AUTOSAR XML (schema 314)
package /ComponentType
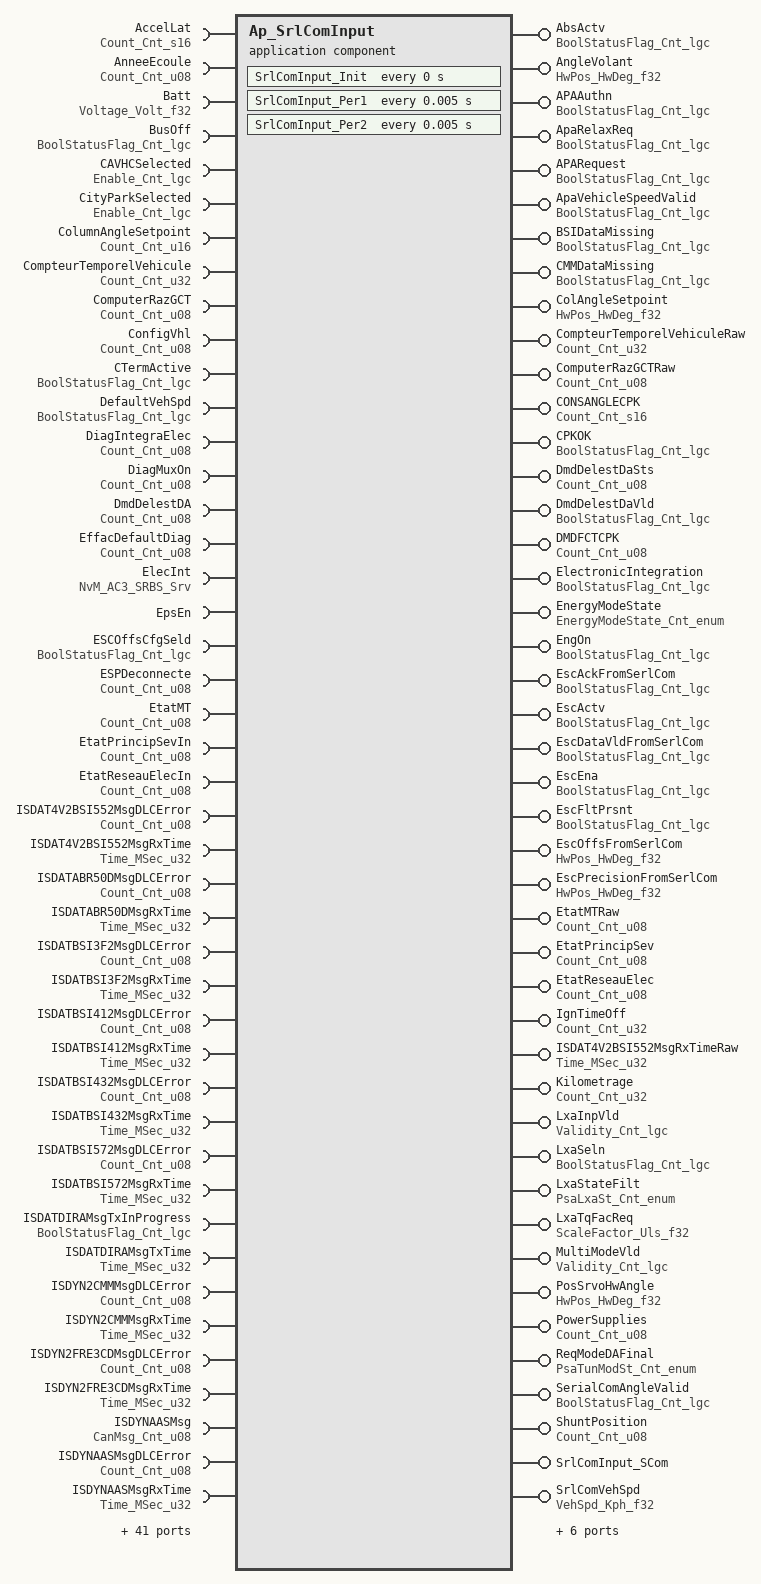
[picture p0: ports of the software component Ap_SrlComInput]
  application software component type Ap_SrlComInput
    50 x provide port:
      AbsActv: unqueued-sender-com-spec{data-element=Cnt_lgc, can-invalidate=false, init-value=D_FALSE_CNT_LGC}, provided-interface=BoolStatusFlag_Cnt_lgc
      AngleVolant: unqueued-sender-com-spec{data-element=HwDeg_f32, can-invalidate=false, init-value=D_ZERO_ULS_F32}, provided-interface=HwPos_HwDeg_f32
      APAAuthn: unqueued-sender-com-spec{data-element=Cnt_lgc, can-invalidate=false, init-value=D_FALSE_CNT_LGC}, provided-interface=BoolStatusFlag_Cnt_lgc
      ApaRelaxReq: unqueued-sender-com-spec{data-element=Cnt_lgc, can-invalidate=false, init-value=D_FALSE_CNT_LGC}, provided-interface=BoolStatusFlag_Cnt_lgc
      APARequest: unqueued-sender-com-spec{data-element=Cnt_lgc, can-invalidate=false, init-value=D_FALSE_CNT_LGC}, provided-interface=BoolStatusFlag_Cnt_lgc
      ApaVehicleSpeedValid: unqueued-sender-com-spec{data-element=Cnt_lgc, can-invalidate=false, init-value=D_FALSE_CNT_LGC}, provided-interface=BoolStatusFlag_Cnt_lgc
      BSIDataMissing: unqueued-sender-com-spec{data-element=Cnt_lgc, can-invalidate=false, init-value=D_TRUE_CNT_LGC}, provided-interface=BoolStatusFlag_Cnt_lgc
      CMMDataMissing: unqueued-sender-com-spec{data-element=Cnt_lgc, can-invalidate=false, init-value=D_TRUE_CNT_LGC}, provided-interface=BoolStatusFlag_Cnt_lgc
      ColAngleSetpoint: unqueued-sender-com-spec{data-element=HwDeg_f32, can-invalidate=false, init-value=D_ZERO_ULS_F32}, provided-interface=HwPos_HwDeg_f32
      CompteurTemporelVehiculeRaw: unqueued-sender-com-spec{data-element=Cnt_u32, can-invalidate=false, init-value=D_ZERO_CNT_U32}, provided-interface=Count_Cnt_u32
      ComputerRazGCTRaw: unqueued-sender-com-spec{data-element=Cnt_u08, can-invalidate=false, init-value=D_ZERO_CNT_U8}, provided-interface=Count_Cnt_u08
      CONSANGLECPK: unqueued-sender-com-spec{data-element=Cnt_s16, can-invalidate=false, init-value=D_ZERO_CNT_S16}, provided-interface=Count_Cnt_s16
      CPKOK: unqueued-sender-com-spec{data-element=Cnt_lgc, can-invalidate=false, init-value=D_FALSE_CNT_LGC}, provided-interface=BoolStatusFlag_Cnt_lgc
      DmdDelestDaSts: unqueued-sender-com-spec{data-element=Cnt_u08, can-invalidate=false, init-value=D_ZERO_CNT_U8}, provided-interface=Count_Cnt_u08
      DmdDelestDaVld: unqueued-sender-com-spec{data-element=Cnt_lgc, can-invalidate=false, init-value=D_FALSE_CNT_LGC}, provided-interface=BoolStatusFlag_Cnt_lgc
      DMDFCTCPK: unqueued-sender-com-spec{data-element=Cnt_u08, can-invalidate=false, init-value=D_ZERO_CNT_U8}, provided-interface=Count_Cnt_u08
      ElectronicIntegration: unqueued-sender-com-spec{data-element=Cnt_lgc, can-invalidate=false, init-value=D_FALSE_CNT_LGC}, provided-interface=BoolStatusFlag_Cnt_lgc
      EnergyModeState: unqueued-sender-com-spec{data-element=Cnt_enum, can-invalidate=false, init-value=D_NORMALINIT_CNT_U16}, provided-interface=EnergyModeState_Cnt_enum
      EngOn: unqueued-sender-com-spec{data-element=Cnt_lgc, can-invalidate=false, init-value=D_FALSE_CNT_LGC}, provided-interface=BoolStatusFlag_Cnt_lgc
      EscAckFromSerlCom: unqueued-sender-com-spec{data-element=Cnt_lgc, can-invalidate=false, init-value=D_FALSE_CNT_LGC}, provided-interface=BoolStatusFlag_Cnt_lgc
      EscActv: unqueued-sender-com-spec{data-element=Cnt_lgc, can-invalidate=false, init-value=D_FALSE_CNT_LGC}, provided-interface=BoolStatusFlag_Cnt_lgc
      EscDataVldFromSerlCom: unqueued-sender-com-spec{data-element=Cnt_lgc, can-invalidate=false, init-value=D_FALSE_CNT_LGC}, provided-interface=BoolStatusFlag_Cnt_lgc
      EscEna: unqueued-sender-com-spec{data-element=Cnt_lgc, can-invalidate=false, init-value=D_FALSE_CNT_LGC}, provided-interface=BoolStatusFlag_Cnt_lgc
      EscFltPrsnt: unqueued-sender-com-spec{data-element=Cnt_lgc, can-invalidate=false, init-value=D_TRUE_CNT_LGC}, provided-interface=BoolStatusFlag_Cnt_lgc
      EscOffsFromSerlCom: unqueued-sender-com-spec{data-element=HwDeg_f32, can-invalidate=false, init-value=D_ZERO_ULS_F32}, provided-interface=HwPos_HwDeg_f32
      EscPrecisionFromSerlCom: unqueued-sender-com-spec{data-element=HwDeg_f32, can-invalidate=false, init-value=D_ZERO_ULS_F32}, provided-interface=HwPos_HwDeg_f32
      EtatMTRaw: unqueued-sender-com-spec{data-element=Cnt_u08, can-invalidate=false, init-value=D_ZERO_CNT_U8}, provided-interface=Count_Cnt_u08
      EtatPrincipSev: unqueued-sender-com-spec{data-element=Cnt_u08, can-invalidate=false, init-value=D_ZERO_CNT_U8}, provided-interface=Count_Cnt_u08
      EtatReseauElec: unqueued-sender-com-spec{data-element=Cnt_u08, can-invalidate=false, init-value=D_ZERO_CNT_U8}, provided-interface=Count_Cnt_u08
      IgnTimeOff: unqueued-sender-com-spec{data-element=Cnt_u32, can-invalidate=false, init-value=D_ZERO_CNT_U32}, provided-interface=Count_Cnt_u32
      ISDAT4V2BSI552MsgRxTimeRaw: unqueued-sender-com-spec{data-element=MSec_u32, can-invalidate=false, init-value=D_ZERO_CNT_U32}, provided-interface=Time_MSec_u32
      Kilometrage: unqueued-sender-com-spec{data-element=Cnt_u32, can-invalidate=false, init-value=D_ZERO_CNT_U32}, provided-interface=Count_Cnt_u32
      LxaInpVld: unqueued-sender-com-spec{data-element=Cnt_lgc, can-invalidate=false, init-value=D_FALSE_CNT_LGC}, provided-interface=Validity_Cnt_lgc
      LxaSeln: unqueued-sender-com-spec{data-element=Cnt_lgc, can-invalidate=false, init-value=D_FALSE_CNT_LGC}, provided-interface=BoolStatusFlag_Cnt_lgc
      LxaStateFilt: unqueued-sender-com-spec{data-element=Cnt_enum, can-invalidate=false, init-value=D_PSALXASTINIT_CNT_ENUM}, provided-interface=PsaLxaSt_Cnt_enum
      LxaTqFacReq: unqueued-sender-com-spec{data-element=Uls_f32, can-invalidate=false, init-value=D_ZERO_ULS_F32}, provided-interface=ScaleFactor_Uls_f32
      MultiModeVld: unqueued-sender-com-spec{data-element=Cnt_lgc, can-invalidate=false, init-value=D_FALSE_CNT_LGC}, provided-interface=Validity_Cnt_lgc
      PosSrvoHwAngle: unqueued-sender-com-spec{data-element=HwDeg_f32, can-invalidate=false, init-value=D_ZERO_ULS_F32}, provided-interface=HwPos_HwDeg_f32
      PowerSupplies: unqueued-sender-com-spec{data-element=Cnt_u08, can-invalidate=false, init-value=D_ZERO_CNT_U8}, provided-interface=Count_Cnt_u08
      ReqModeDAFinal: unqueued-sender-com-spec{data-element=Cnt_enum, can-invalidate=false, init-value=D_PSATUNMODSTINIT_CNT_ENUM}, provided-interface=PsaTunModSt_Cnt_enum
      SerialComAngleValid: unqueued-sender-com-spec{data-element=Cnt_lgc, can-invalidate=false, init-value=D_FALSE_CNT_LGC}, provided-interface=BoolStatusFlag_Cnt_lgc
      ShuntPosition: unqueued-sender-com-spec{data-element=Cnt_u08, can-invalidate=false, init-value=D_ZERO_CNT_U8}, provided-interface=Count_Cnt_u08
      SrlComInput_SCom: provided-interface=SrlComInput_SCom
        provided-com-specs:
          operation=GetNetworkDiagFltAcc, queue-length=1
          operation=ManualVehSpd, queue-length=1
          operation=ResetTimers, queue-length=1
          operation=VehSpdControl, queue-length=1
      SrlComVehSpd: unqueued-sender-com-spec{data-element=Kph_f32, can-invalidate=false, init-value=D_ZERO_ULS_F32}, provided-interface=VehSpd_Kph_f32
      ValidEngineStatus: unqueued-sender-com-spec{data-element=Cnt_lgc, can-invalidate=false, init-value=D_FALSE_CNT_LGC}, provided-interface=BoolStatusFlag_Cnt_lgc
      VehicleLatAccel: unqueued-sender-com-spec{data-element=MpSecSq_f32, can-invalidate=false, init-value=D_ZERO_ULS_F32}, provided-interface=VehAccel_MpSecSq_f32
      VehicleLatAccelValid: unqueued-sender-com-spec{data-element=Cnt_lgc, can-invalidate=false, init-value=D_FALSE_CNT_LGC}, provided-interface=Validity_Cnt_lgc
      VehicleSpeedValid: unqueued-sender-com-spec{data-element=Cnt_lgc, can-invalidate=false, init-value=D_FALSE_CNT_LGC}, provided-interface=BoolStatusFlag_Cnt_lgc
      VehTimeValid: unqueued-sender-com-spec{data-element=Cnt_lgc, can-invalidate=false, init-value=D_FALSE_CNT_LGC}, provided-interface=BoolStatusFlag_Cnt_lgc
      VVHType: unqueued-sender-com-spec{data-element=Cnt_u08, can-invalidate=false, init-value=D_ZERO_CNT_U8}, provided-interface=Count_Cnt_u08
    85 x require port:
      AccelLat: unqueued-receiver-com-spec{data-element=Cnt_s16, init-value=D_ZERO_CNT_S16}, required-interface=Count_Cnt_s16
      AnneeEcoule: unqueued-receiver-com-spec{data-element=Cnt_u08, init-value=D_ZERO_CNT_U8}, required-interface=Count_Cnt_u08
      Batt: unqueued-receiver-com-spec{data-element=Volt_f32, init-value=D_ZERO_ULS_F32}, required-interface=Voltage_Volt_f32
      BusOff: unqueued-receiver-com-spec{data-element=Cnt_lgc, init-value=D_FALSE_CNT_LGC}, required-interface=BoolStatusFlag_Cnt_lgc
      CAVHCSelected: unqueued-receiver-com-spec{data-element=Cnt_lgc, init-value=D_FALSE_CNT_LGC}, required-interface=Enable_Cnt_lgc
      CityParkSelected: unqueued-receiver-com-spec{data-element=Cnt_lgc, init-value=D_FALSE_CNT_LGC}, required-interface=Enable_Cnt_lgc
      ColumnAngleSetpoint: unqueued-receiver-com-spec{data-element=Cnt_u16, init-value=D_ZERO_CNT_U16}, required-interface=Count_Cnt_u16
      CompteurTemporelVehicule: unqueued-receiver-com-spec{data-element=Cnt_u32, init-value=D_ZERO_CNT_U32}, required-interface=Count_Cnt_u32
      ComputerRazGCT: unqueued-receiver-com-spec{data-element=Cnt_u08, init-value=D_ZERO_CNT_U8}, required-interface=Count_Cnt_u08
      ConfigVhl: unqueued-receiver-com-spec{data-element=Cnt_u08, init-value=D_ZERO_CNT_U8}, required-interface=Count_Cnt_u08
      CTermActive: unqueued-receiver-com-spec{data-element=Cnt_lgc, init-value=D_FALSE_CNT_LGC}, required-interface=BoolStatusFlag_Cnt_lgc
      DefaultVehSpd: unqueued-receiver-com-spec{data-element=Cnt_lgc, init-value=D_FALSE_CNT_LGC}, required-interface=BoolStatusFlag_Cnt_lgc
      DiagIntegraElec: unqueued-receiver-com-spec{data-element=Cnt_u08, init-value=D_ZERO_CNT_U8}, required-interface=Count_Cnt_u08
      DiagMuxOn: unqueued-receiver-com-spec{data-element=Cnt_u08, init-value=D_ZERO_CNT_U8}, required-interface=Count_Cnt_u08
      DmdDelestDA: unqueued-receiver-com-spec{data-element=Cnt_u08, init-value=D_ZERO_CNT_U8}, required-interface=Count_Cnt_u08
      EffacDefaultDiag: unqueued-receiver-com-spec{data-element=Cnt_u08, init-value=D_ZERO_CNT_U8}, required-interface=Count_Cnt_u08
      ElecInt: required-com-specs=[EraseBlock, GetErrorStatus, InvalidateNvBlock, ReadBlock, SetRamBlockStatus, WriteBlock], required-interface=NvM_AC3_SRBS_Srv
      EpsEn: client-com-spec=OP_GET, required-interface=EpsEn
      ESCOffsCfgSeld: unqueued-receiver-com-spec{data-element=Cnt_lgc, init-value=D_FALSE_CNT_LGC}, required-interface=BoolStatusFlag_Cnt_lgc
      ESPDeconnecte: unqueued-receiver-com-spec{data-element=Cnt_u08, init-value=D_ONE_CNT_U8}, required-interface=Count_Cnt_u08
      EtatMT: unqueued-receiver-com-spec{data-element=Cnt_u08, init-value=D_ZERO_CNT_U8}, required-interface=Count_Cnt_u08
      EtatPrincipSevIn: unqueued-receiver-com-spec{data-element=Cnt_u08, init-value=D_ZERO_CNT_U8}, required-interface=Count_Cnt_u08
      EtatReseauElecIn: unqueued-receiver-com-spec{data-element=Cnt_u08, init-value=D_ZERO_CNT_U8}, required-interface=Count_Cnt_u08
      ISDAT4V2BSI552MsgDLCError: unqueued-receiver-com-spec{data-element=Cnt_u08, init-value=D_ZERO_CNT_U8}, required-interface=Count_Cnt_u08
      ISDAT4V2BSI552MsgRxTime: unqueued-receiver-com-spec{data-element=MSec_u32, init-value=D_ZERO_CNT_U32}, required-interface=Time_MSec_u32
      ISDATABR50DMsgDLCError: unqueued-receiver-com-spec{data-element=Cnt_u08, init-value=D_ZERO_CNT_U8}, required-interface=Count_Cnt_u08
      ISDATABR50DMsgRxTime: unqueued-receiver-com-spec{data-element=MSec_u32, init-value=D_ZERO_CNT_U32}, required-interface=Time_MSec_u32
      ISDATBSI3F2MsgDLCError: unqueued-receiver-com-spec{data-element=Cnt_u08, init-value=D_ZERO_CNT_U8}, required-interface=Count_Cnt_u08
      ISDATBSI3F2MsgRxTime: unqueued-receiver-com-spec{data-element=MSec_u32, init-value=D_ZERO_CNT_U32}, required-interface=Time_MSec_u32
      ISDATBSI412MsgDLCError: unqueued-receiver-com-spec{data-element=Cnt_u08, init-value=D_ZERO_CNT_U8}, required-interface=Count_Cnt_u08
      ISDATBSI412MsgRxTime: unqueued-receiver-com-spec{data-element=MSec_u32, init-value=D_ZERO_CNT_U32}, required-interface=Time_MSec_u32
      ISDATBSI432MsgDLCError: unqueued-receiver-com-spec{data-element=Cnt_u08, init-value=D_ZERO_CNT_U8}, required-interface=Count_Cnt_u08
      ISDATBSI432MsgRxTime: unqueued-receiver-com-spec{data-element=MSec_u32, init-value=D_ZERO_CNT_U32}, required-interface=Time_MSec_u32
      ISDATBSI572MsgDLCError: unqueued-receiver-com-spec{data-element=Cnt_u08, init-value=D_ZERO_CNT_U8}, required-interface=Count_Cnt_u08
      ISDATBSI572MsgRxTime: unqueued-receiver-com-spec{data-element=MSec_u32, init-value=D_ZERO_CNT_U32}, required-interface=Time_MSec_u32
      ISDATDIRAMsgTxInProgress: unqueued-receiver-com-spec{data-element=Cnt_lgc, init-value=D_FALSE_CNT_LGC}, required-interface=BoolStatusFlag_Cnt_lgc
      ISDATDIRAMsgTxTime: unqueued-receiver-com-spec{data-element=MSec_u32, init-value=D_ZERO_CNT_U32}, required-interface=Time_MSec_u32
      ISDYN2CMMMsgDLCError: unqueued-receiver-com-spec{data-element=Cnt_u08, init-value=D_ZERO_CNT_U8}, required-interface=Count_Cnt_u08
      ISDYN2CMMMsgRxTime: unqueued-receiver-com-spec{data-element=MSec_u32, init-value=D_ZERO_CNT_U32}, required-interface=Time_MSec_u32
      ISDYN2FRE3CDMsgDLCError: unqueued-receiver-com-spec{data-element=Cnt_u08, init-value=D_ZERO_CNT_U8}, required-interface=Count_Cnt_u08
      ISDYN2FRE3CDMsgRxTime: unqueued-receiver-com-spec{data-element=MSec_u32, init-value=D_ZERO_CNT_U32}, required-interface=Time_MSec_u32
      ISDYNAASMsg: unqueued-receiver-com-spec{data-element=Cnt_u08, init-value=T_CANMSGINIT_CNT_U08}, required-interface=CanMsg_Cnt_u08
      ISDYNAASMsgDLCError: unqueued-receiver-com-spec{data-element=Cnt_u08, init-value=D_ZERO_CNT_U8}, required-interface=Count_Cnt_u08
      ISDYNAASMsgRxTime: unqueued-receiver-com-spec{data-element=MSec_u32, init-value=D_ZERO_CNT_U32}, required-interface=Time_MSec_u32
      ISDYNABRMsg: unqueued-receiver-com-spec{data-element=Cnt_u08, init-value=T_CANMSGINIT_CNT_U08}, required-interface=CanMsg_Cnt_u08
      ISDYNABRMsgDLCError: unqueued-receiver-com-spec{data-element=Cnt_u08, init-value=D_ZERO_CNT_U8}, required-interface=Count_Cnt_u08
      ISDYNABRMsgRxTime: unqueued-receiver-com-spec{data-element=MSec_u32, init-value=D_ZERO_CNT_U32}, required-interface=Time_MSec_u32
      ISDYNCDS34DMsgDLCError: unqueued-receiver-com-spec{data-element=Cnt_u08, init-value=D_ZERO_CNT_U8}, required-interface=Count_Cnt_u08
      ISDYNCDS34DMsgRxTime: unqueued-receiver-com-spec{data-element=MSec_u32, init-value=D_ZERO_CNT_U32}, required-interface=Time_MSec_u32
      ISDYNCMM208MsgDLCError: unqueued-receiver-com-spec{data-element=Cnt_u08, init-value=D_ZERO_CNT_U8}, required-interface=Count_Cnt_u08
      ISDYNCMM208MsgRxTime: unqueued-receiver-com-spec{data-element=MSec_u32, init-value=D_ZERO_CNT_U32}, required-interface=Time_MSec_u32
      ISDYNCMM388MsgDLCError: unqueued-receiver-com-spec{data-element=Cnt_u08, init-value=D_ZERO_CNT_U8}, required-interface=Count_Cnt_u08
      ISDYNCMM388MsgRxTime: unqueued-receiver-com-spec{data-element=MSec_u32, init-value=D_ZERO_CNT_U32}, required-interface=Time_MSec_u32
      ISDYNVOLMsg: unqueued-receiver-com-spec{data-element=Cnt_u08, init-value=T_CANMSGINIT_CNT_U08}, required-interface=CanMsg_Cnt_u08
      ISDYNVOLMsgDLCError: unqueued-receiver-com-spec{data-element=Cnt_u08, init-value=D_ZERO_CNT_U8}, required-interface=Count_Cnt_u08
      ISDYNVOLMsgRxTime: unqueued-receiver-com-spec{data-element=MSec_u32, init-value=D_ZERO_CNT_U32}, required-interface=Time_MSec_u32
      ISINTEELECTRONBSIMsgRxTime: unqueued-receiver-com-spec{data-element=MSec_u32, init-value=D_ZERO_CNT_U32}, required-interface=Time_MSec_u32
      JourEcoule: unqueued-receiver-com-spec{data-element=Cnt_u16, init-value=D_ZERO_CNT_U16}, required-interface=Count_Cnt_u16
      KilometrageIn: unqueued-receiver-com-spec{data-element=Cnt_u32, init-value=D_ZERO_CNT_U32}, required-interface=Count_Cnt_u32
      LKAState: unqueued-receiver-com-spec{data-element=Cnt_u08, init-value=D_ZERO_CNT_U8}, required-interface=Count_Cnt_u08
      LKATrqFactReq: unqueued-receiver-com-spec{data-element=Cnt_u08, init-value=D_ZERO_CNT_U8}, required-interface=Count_Cnt_u08
      LXAActivation: unqueued-receiver-com-spec{data-element=Cnt_u08, init-value=D_ZERO_CNT_U8}, required-interface=Count_Cnt_u08
      LXASelected: unqueued-receiver-com-spec{data-element=Cnt_lgc, init-value=D_FALSE_CNT_LGC}, required-interface=Enable_Cnt_lgc
      ModeDiag: unqueued-receiver-com-spec{data-element=Cnt_u08, init-value=D_ZERO_CNT_U8}, required-interface=Count_Cnt_u08
      MultimodeSelected: unqueued-receiver-com-spec{data-element=Cnt_lgc, init-value=D_FALSE_CNT_LGC}, required-interface=Enable_Cnt_lgc
      NxtrDiagMgr: required-com-specs=[GetNTCActive, GetNTCFailed, GetNTCStatus, SetNTCStatus], required-interface=NxtrDiagMgr
      PowerSuppliesIn: unqueued-receiver-com-spec{data-element=Cnt_u08, init-value=D_ZERO_CNT_U8}, required-interface=Count_Cnt_u08
      PROTOHS1DYNUCF5CDMsg: unqueued-receiver-com-spec{data-element=Cnt_u08, init-value=T_CANMSGINIT_CNT_U08}, required-interface=CanMsg_Cnt_u08
      PROTOHS1DYNUCF5CDMsgDLCError: unqueued-receiver-com-spec{data-element=Cnt_u08, init-value=D_ZERO_CNT_U8}, required-interface=Count_Cnt_u08
      PROTOHS1DYNUCF5CDMsgRxTime: unqueued-receiver-com-spec{data-element=MSec_u32, init-value=D_ZERO_CNT_U32}, required-interface=Time_MSec_u32
      RegulAbr: unqueued-receiver-com-spec{data-element=Cnt_u08, init-value=D_ZERO_CNT_U8}, required-interface=Count_Cnt_u08
      RegulEsp: unqueued-receiver-com-spec{data-element=Cnt_u08, init-value=D_ZERO_CNT_U8}, required-interface=Count_Cnt_u08
      ReqLampeDefEsp: unqueued-receiver-com-spec{data-element=Cnt_u08, init-value=D_ZERO_CNT_U8}, required-interface=Count_Cnt_u08
      ReqModeDA: unqueued-receiver-com-spec{data-element=Cnt_u08, init-value=D_ZERO_CNT_U8}, required-interface=Count_Cnt_u08
      RxMsgsSrlComSvcDft: unqueued-receiver-com-spec{data-element=Cnt_lgc, init-value=D_FALSE_CNT_LGC}, required-interface=Enable_Cnt_lgc
      SecondeEcoulee: unqueued-receiver-com-spec{data-element=Cnt_u32, init-value=D_ZERO_CNT_U32}, required-interface=Count_Cnt_u32
      ShuntPositionIn: unqueued-receiver-com-spec{data-element=Cnt_u08, init-value=D_ZERO_CNT_U8}, required-interface=Count_Cnt_u08
      ShutdownTime: required-com-specs=[EraseBlock, GetErrorStatus, InvalidateNvBlock, ReadBlock, SetRamBlockStatus, WriteBlock], required-interface=NvM_AC3_SRBS_Srv
      SrlComDriver_SCom: required-com-specs=[ElecIntStart, ElecIntStop, GetBusOffCounter, SendMsgOnChange], required-interface=SrlComDriver_SCom
      STTdSelected: unqueued-receiver-com-spec{data-element=Cnt_lgc, init-value=D_FALSE_CNT_LGC}, required-interface=Enable_Cnt_lgc
      SystemState: required-interface=SystemState
      SystemTime: required-interface=SystemTime
        required-com-specs:
          DtrmnElapsedTime_mS_u16
          DtrmnElapsedTime_mS_u32
          DtrmnElapsedTime_uS_u16
          DtrmnElapsedTime_uS_u32
          GetSystemTime_mS_u32
          GetSystemTime_uS_u32
      VehicleSpeed: unqueued-receiver-com-spec{data-element=Kph_f32, init-value=D_ZERO_ULS_F32}, required-interface=VehSpd_Kph_f32
      VHHTYPE: required-com-specs=[EraseBlock, GetErrorStatus, InvalidateNvBlock, ReadBlock, SetRamBlockStatus, WriteBlock], required-interface=NvM_AC3_SRBS_Srv
      VitesseVehicleBV: unqueued-receiver-com-spec{data-element=Cnt_u16, init-value=D_ZERO_CNT_U16}, required-interface=Count_Cnt_u16
  internal behavior Ap_SrlComInput_InternalBehavior: component=Ap_SrlComInput
    timing event SrlComInput_InitEvent: start-on-event=SrlComInput_Init, period=0
    16 x data received event:
      DRT_SrlComInput_MsgIsDat4V2Bsi_552_ISDAT4V2BSI552MsgRxTime_MSec_u32: start-on-event=SrlComInput_MsgIsDat4V2Bsi_552, data=ISDAT4V2BSI552MsgRxTime.MSec_u32
      DRT_SrlComInput_MsgIsDatAbr_50D_ISDATABR50DMsgRxTime_MSec_u32: start-on-event=SrlComInput_MsgIsDatAbr_50D, data=ISDATABR50DMsgRxTime.MSec_u32
      DRT_SrlComInput_MsgIsDatBsi_3F2_ISDATBSI3F2MsgRxTime_MSec_u32: start-on-event=SrlComInput_MsgIsDatBsi_3F2, data=ISDATBSI3F2MsgRxTime.MSec_u32
      DRT_SrlComInput_MsgIsDatBsi_412_ISDATBSI412MsgRxTime_MSec_u32: start-on-event=SrlComInput_MsgIsDatBsi_412, data=ISDATBSI412MsgRxTime.MSec_u32
      DRT_SrlComInput_MsgIsDatBsi_432_ISDATBSI432MsgRxTime_MSec_u32: start-on-event=SrlComInput_MsgIsDatBsi_432, data=ISDATBSI432MsgRxTime.MSec_u32
      DRT_SrlComInput_MsgIsDatBsi_572_ISDATBSI572MsgRxTime_MSec_u32: start-on-event=SrlComInput_MsgIsDatBsi_572, data=ISDATBSI572MsgRxTime.MSec_u32
      DRT_SrlComInput_MsgIsDyn2Cmm_348_ISDYN2CMMMsgRxTime_MSec_u32: start-on-event=SrlComInput_MsgIsDyn2Cmm_348, data=ISDYN2CMMMsgRxTime.MSec_u32
      DRT_SrlComInput_MsgIsDyn2Fre_3CD_ISDYN2FRE3CDMsgRxTime_MSec_u32: start-on-event=SrlComInput_MsgIsDyn2Fre_3CD, data=ISDYN2FRE3CDMsgRxTime.MSec_u32
      DRT_SrlComInput_MsgIsDynAas_2EB_ISDYNAASMsgRxTime_MSec_u32: start-on-event=SrlComInput_MsgIsDynAas_2EB, data=ISDYNAASMsgRxTime.MSec_u32
      DRT_SrlComInput_MsgIsDynAbr_38D_ISDYNABRMsgRxTime_MSec_u32: start-on-event=SrlComInput_MsgIsDynAbr_38D, data=ISDYNABRMsgRxTime.MSec_u32
      DRT_SrlComInput_MsgIsDynCds_34D_ISDYNCDS34DMsgRxTime_MSec_u32: start-on-event=SrlComInput_MsgIsDynCds_34D, data=ISDYNCDS34DMsgRxTime.MSec_u32
      DRT_SrlComInput_MsgIsDynCmm_208_ISDYNCMM208MsgRxTime_MSec_u32: start-on-event=SrlComInput_MsgIsDynCmm_208, data=ISDYNCMM208MsgRxTime.MSec_u32
      DRT_SrlComInput_MsgIsDynCmm_388_ISDYNCMM388MsgRxTime_MSec_u32: start-on-event=SrlComInput_MsgIsDynCmm_388, data=ISDYNCMM388MsgRxTime.MSec_u32
      DRT_SrlComInput_MsgIsDynVol_305_ISDYNVOLMsgRxTime_MSec_u32: start-on-event=SrlComInput_MsgIsDynVol_305, data=ISDYNVOLMsgRxTime.MSec_u32
      DRT_SrlComInput_MsgIsInteElectronBsi_092_ISINTEELECTRONBSIMsgRxTime_MSec_u32: start-on-event=SrlComInput_MsgIsInteElectronBsi_092, data=ISINTEELECTRONBSIMsgRxTime.MSec_u32
      DRT_SrlComInput_MsgProtoHs1DynUcf_5CD_PROTOHS1DYNUCF5CDMsgRxTime_MSec_u32: start-on-event=SrlComInput_MsgProtoHs1DynUcf_5CD, data=PROTOHS1DYNUCF5CDMsgRxTime.MSec_u32
    timing event TMT_SrlComInput_Per1: start-on-event=SrlComInput_Per1, period=0.005
    timing event TMT_SrlComInput_Per2: start-on-event=SrlComInput_Per2, period=0.005
    4 x operation invoked event:
      OIT_SrlComInput_SCom_GetNetworkDiagFltAcc_SrlComInput_SCom_GetNetworkDiagFltAcc: start-on-event=SrlComInput_SCom_GetNetworkDiagFltAcc, operation=SrlComInput_SCom.GetNetworkDiagFltAcc
      OIT_SrlComInput_SCom_ManualVehSpd_SrlComInput_SCom_ManualVehSpd: start-on-event=SrlComInput_SCom_ManualVehSpd, operation=SrlComInput_SCom.ManualVehSpd
      OIT_SrlComInput_SCom_ResetTimers_SrlComInput_SCom_ResetTimers: start-on-event=SrlComInput_SCom_ResetTimers, operation=SrlComInput_SCom.ResetTimers
      OIT_SrlComInput_SCom_VehSpdControl_SrlComInput_SCom_VehSpdControl: start-on-event=SrlComInput_SCom_VehSpdControl, operation=SrlComInput_SCom.VehSpdControl
    mode switch event MST_SrlComInput_Trns1_0: start-on-event=SrlComInput_Trns1, activation=ENTRY, mode=SystemState.Mode.OFF
    mode switch event MST_SrlComInput_Trns2_0: start-on-event=SrlComInput_Trns2, activation=EXIT, mode=SystemState.Mode.OFF
    exclusive area DmdDelestDa
    exclusive area EaShutdownTimeData
    per instance memory ElecIntData: type=Boolean, type-definition=/DataType/Boolean
    per instance memory ShutdownTimeData: type=ShutdownTimeType, type-definition=/DataType/ShutdownTimeType
    per instance memory VVHTYPEData: type=UInt8, type-definition=/DataType/UInt8
    port-api-options:
      enable-take-address=false, indirect-api=false, port=AbsActv
      enable-take-address=false, indirect-api=false, port=AccelLat
      enable-take-address=false, indirect-api=false, port=AngleVolant
      enable-take-address=false, indirect-api=false, port=AnneeEcoule
      enable-take-address=false, indirect-api=false, port=APAAuthn
      enable-take-address=false, indirect-api=false, port=ApaRelaxReq
      enable-take-address=false, indirect-api=false, port=APARequest
      enable-take-address=false, indirect-api=false, port=ApaVehicleSpeedValid
      enable-take-address=false, indirect-api=false, port=Batt
      enable-take-address=false, indirect-api=false, port=BSIDataMissing
      enable-take-address=false, indirect-api=false, port=BusOff
      enable-take-address=false, indirect-api=false, port=CAVHCSelected
      enable-take-address=false, indirect-api=false, port=CityParkSelected
      enable-take-address=false, indirect-api=false, port=CMMDataMissing
      enable-take-address=false, indirect-api=false, port=ColAngleSetpoint
      enable-take-address=false, indirect-api=false, port=ColumnAngleSetpoint
      enable-take-address=false, indirect-api=false, port=CompteurTemporelVehicule
      enable-take-address=false, indirect-api=false, port=CompteurTemporelVehiculeRaw
      enable-take-address=false, indirect-api=false, port=ComputerRazGCT
      enable-take-address=false, indirect-api=false, port=ComputerRazGCTRaw
      enable-take-address=false, indirect-api=false, port=ConfigVhl
      enable-take-address=false, indirect-api=false, port=CONSANGLECPK
      enable-take-address=false, indirect-api=false, port=CPKOK
      enable-take-address=false, indirect-api=false, port=CTermActive
      enable-take-address=false, indirect-api=false, port=DefaultVehSpd
      enable-take-address=false, indirect-api=false, port=DiagIntegraElec
      enable-take-address=false, indirect-api=false, port=DiagMuxOn
      enable-take-address=false, indirect-api=false, port=DmdDelestDA
      enable-take-address=false, indirect-api=false, port=DmdDelestDaSts
      enable-take-address=false, indirect-api=false, port=DmdDelestDaVld
      enable-take-address=false, indirect-api=false, port=DMDFCTCPK
      enable-take-address=false, indirect-api=false, port=EffacDefaultDiag
      enable-take-address=false, indirect-api=false, port=ElecInt
      enable-take-address=false, indirect-api=false, port=ElectronicIntegration
      enable-take-address=false, indirect-api=false, port=EnergyModeState
      enable-take-address=false, indirect-api=false, port=EngOn
      enable-take-address=false, indirect-api=false, port=EpsEn
      enable-take-address=false, indirect-api=false, port=EscAckFromSerlCom
      enable-take-address=false, indirect-api=false, port=EscActv
      enable-take-address=false, indirect-api=false, port=EscDataVldFromSerlCom
      enable-take-address=false, indirect-api=false, port=EscEna
      enable-take-address=false, indirect-api=false, port=EscFltPrsnt
      enable-take-address=false, indirect-api=false, port=ESCOffsCfgSeld
      enable-take-address=false, indirect-api=false, port=EscOffsFromSerlCom
      enable-take-address=false, indirect-api=false, port=EscPrecisionFromSerlCom
      enable-take-address=false, indirect-api=false, port=ESPDeconnecte
      enable-take-address=false, indirect-api=false, port=EtatMT
      enable-take-address=false, indirect-api=false, port=EtatMTRaw
      enable-take-address=false, indirect-api=false, port=EtatPrincipSev
      enable-take-address=false, indirect-api=false, port=EtatPrincipSevIn
      enable-take-address=false, indirect-api=false, port=EtatReseauElec
      enable-take-address=false, indirect-api=false, port=EtatReseauElecIn
      enable-take-address=false, indirect-api=false, port=IgnTimeOff
      enable-take-address=false, indirect-api=false, port=ISDAT4V2BSI552MsgDLCError
      enable-take-address=false, indirect-api=false, port=ISDAT4V2BSI552MsgRxTime
      enable-take-address=false, indirect-api=false, port=ISDAT4V2BSI552MsgRxTimeRaw
      enable-take-address=false, indirect-api=false, port=ISDATABR50DMsgDLCError
      enable-take-address=false, indirect-api=false, port=ISDATABR50DMsgRxTime
      enable-take-address=false, indirect-api=false, port=ISDATBSI3F2MsgDLCError
      enable-take-address=false, indirect-api=false, port=ISDATBSI3F2MsgRxTime
      enable-take-address=false, indirect-api=false, port=ISDATBSI412MsgDLCError
      enable-take-address=false, indirect-api=false, port=ISDATBSI412MsgRxTime
      enable-take-address=false, indirect-api=false, port=ISDATBSI432MsgDLCError
      enable-take-address=false, indirect-api=false, port=ISDATBSI432MsgRxTime
      enable-take-address=false, indirect-api=false, port=ISDATBSI572MsgDLCError
      enable-take-address=false, indirect-api=false, port=ISDATBSI572MsgRxTime
      enable-take-address=false, indirect-api=false, port=ISDATDIRAMsgTxInProgress
      enable-take-address=false, indirect-api=false, port=ISDATDIRAMsgTxTime
      enable-take-address=false, indirect-api=false, port=ISDYN2CMMMsgDLCError
      enable-take-address=false, indirect-api=false, port=ISDYN2CMMMsgRxTime
      enable-take-address=false, indirect-api=false, port=ISDYN2FRE3CDMsgDLCError
      enable-take-address=false, indirect-api=false, port=ISDYN2FRE3CDMsgRxTime
      enable-take-address=false, indirect-api=false, port=ISDYNAASMsg
      enable-take-address=false, indirect-api=false, port=ISDYNAASMsgDLCError
      enable-take-address=false, indirect-api=false, port=ISDYNAASMsgRxTime
      enable-take-address=false, indirect-api=false, port=ISDYNABRMsg
      enable-take-address=false, indirect-api=false, port=ISDYNABRMsgDLCError
      enable-take-address=false, indirect-api=false, port=ISDYNABRMsgRxTime
      enable-take-address=false, indirect-api=false, port=ISDYNCDS34DMsgDLCError
      enable-take-address=false, indirect-api=false, port=ISDYNCDS34DMsgRxTime
      enable-take-address=false, indirect-api=false, port=ISDYNCMM208MsgDLCError
      enable-take-address=false, indirect-api=false, port=ISDYNCMM208MsgRxTime
      enable-take-address=false, indirect-api=false, port=ISDYNCMM388MsgDLCError
      enable-take-address=false, indirect-api=false, port=ISDYNCMM388MsgRxTime
      enable-take-address=false, indirect-api=false, port=ISDYNVOLMsg
      enable-take-address=false, indirect-api=false, port=ISDYNVOLMsgDLCError
      enable-take-address=false, indirect-api=false, port=ISDYNVOLMsgRxTime
      enable-take-address=false, indirect-api=false, port=ISINTEELECTRONBSIMsgRxTime
      enable-take-address=false, indirect-api=false, port=JourEcoule
      enable-take-address=false, indirect-api=false, port=Kilometrage
      enable-take-address=false, indirect-api=false, port=KilometrageIn
      enable-take-address=false, indirect-api=false, port=LKAState
      enable-take-address=false, indirect-api=false, port=LKATrqFactReq
      enable-take-address=false, indirect-api=false, port=LXAActivation
      enable-take-address=false, indirect-api=false, port=LxaInpVld
      enable-take-address=false, indirect-api=false, port=LXASelected
      enable-take-address=false, indirect-api=false, port=LxaSeln
      enable-take-address=false, indirect-api=false, port=LxaStateFilt
      enable-take-address=false, indirect-api=false, port=LxaTqFacReq
      enable-take-address=false, indirect-api=false, port=ModeDiag
      enable-take-address=false, indirect-api=false, port=MultimodeSelected
      enable-take-address=false, indirect-api=false, port=MultiModeVld
      enable-take-address=false, indirect-api=false, port=NxtrDiagMgr
      enable-take-address=false, indirect-api=false, port=PosSrvoHwAngle
      enable-take-address=false, indirect-api=false, port=PowerSupplies
      enable-take-address=false, indirect-api=false, port=PowerSuppliesIn
      enable-take-address=false, indirect-api=false, port=PROTOHS1DYNUCF5CDMsg
      enable-take-address=false, indirect-api=false, port=PROTOHS1DYNUCF5CDMsgDLCError
      enable-take-address=false, indirect-api=false, port=PROTOHS1DYNUCF5CDMsgRxTime
      enable-take-address=false, indirect-api=false, port=RegulAbr
      enable-take-address=false, indirect-api=false, port=RegulEsp
      enable-take-address=false, indirect-api=false, port=ReqLampeDefEsp
      enable-take-address=false, indirect-api=false, port=ReqModeDA
      enable-take-address=false, indirect-api=false, port=ReqModeDAFinal
      enable-take-address=false, indirect-api=false, port=RxMsgsSrlComSvcDft
      enable-take-address=false, indirect-api=false, port=SecondeEcoulee
      enable-take-address=false, indirect-api=false, port=SerialComAngleValid
      enable-take-address=false, indirect-api=false, port=ShuntPosition
      enable-take-address=false, indirect-api=false, port=ShuntPositionIn
      enable-take-address=false, indirect-api=false, port=ShutdownTime
      enable-take-address=false, indirect-api=false, port=SrlComDriver_SCom
      enable-take-address=false, indirect-api=false, port=SrlComInput_SCom
      enable-take-address=false, indirect-api=false, port=SrlComVehSpd
      enable-take-address=false, indirect-api=false, port=STTdSelected
      enable-take-address=false, indirect-api=false, port=SystemState
      enable-take-address=false, indirect-api=false, port=SystemTime
      enable-take-address=false, indirect-api=false, port=ValidEngineStatus
      enable-take-address=false, indirect-api=false, port=VehicleLatAccel
      enable-take-address=false, indirect-api=false, port=VehicleLatAccelValid
      enable-take-address=false, indirect-api=false, port=VehicleSpeed
      enable-take-address=false, indirect-api=false, port=VehicleSpeedValid
      enable-take-address=false, indirect-api=false, port=VehTimeValid
      enable-take-address=false, indirect-api=false, port=VHHTYPE
      enable-take-address=false, indirect-api=false, port=VitesseVehicleBV
      enable-take-address=false, indirect-api=false, port=VVHType
    25 x runnable:
      SrlComInput_Init
        6 x data read access:
          READ_CAVHCSelected_Cnt_lgc: data-element=CAVHCSelected.Cnt_lgc
          READ_CityParkSelected_Cnt_lgc: data-element=CityParkSelected.Cnt_lgc
          READ_ESCOffsCfgSeld_Cnt_lgc: data-element=ESCOffsCfgSeld.Cnt_lgc
          READ_LXASelected_Cnt_lgc: data-element=LXASelected.Cnt_lgc
          READ_MultimodeSelected_Cnt_lgc: data-element=MultimodeSelected.Cnt_lgc
          READ_STTdSelected_Cnt_lgc: data-element=STTdSelected.Cnt_lgc
        data send point SEND_VVHType_Cnt_u08: data-element=VVHType.Cnt_u08
        8 x data write access:
          WRITE_ApaVehicleSpeedValid_Cnt_lgc: data-element=ApaVehicleSpeedValid.Cnt_lgc
          WRITE_CPKOK_Cnt_lgc: data-element=CPKOK.Cnt_lgc
          WRITE_ElectronicIntegration_Cnt_lgc: data-element=ElectronicIntegration.Cnt_lgc
          WRITE_EnergyModeState_Cnt_enum: data-element=EnergyModeState.Cnt_enum
          WRITE_EscPrecisionFromSerlCom_HwDeg_f32: data-element=EscPrecisionFromSerlCom.HwDeg_f32
          WRITE_LxaInpVld_Cnt_lgc: data-element=LxaInpVld.Cnt_lgc
          WRITE_MultiModeVld_Cnt_lgc: data-element=MultiModeVld.Cnt_lgc
          WRITE_SrlComVehSpd_Kph_f32: data-element=SrlComVehSpd.Kph_f32
        sync call SC_NxtrDiagMgr_GetNTCFailed: operation=NxtrDiagMgr.GetNTCFailed, timeout=0
        sync call SC_NxtrDiagMgr_SetNTCStatus: operation=NxtrDiagMgr.SetNTCStatus, timeout=0
        sync call SC_SystemTime_GetSystemTime_mS_u32: operation=SystemTime.GetSystemTime_mS_u32, timeout=0
      SrlComInput_MsgIsDat4V2Bsi_552: can-enter-exclusive-area=EaShutdownTimeData
        7 x data receive point:
          REC_AnneeEcoule_Cnt_u08: data-element=AnneeEcoule.Cnt_u08
          REC_CompteurTemporelVehicule_Cnt_u32: data-element=CompteurTemporelVehicule.Cnt_u32
          REC_ISDAT4V2BSI552MsgDLCError_Cnt_u08: data-element=ISDAT4V2BSI552MsgDLCError.Cnt_u08
          REC_ISDAT4V2BSI552MsgRxTime_MSec_u32: data-element=ISDAT4V2BSI552MsgRxTime.MSec_u32
          REC_JourEcoule_Cnt_u16: data-element=JourEcoule.Cnt_u16
          REC_KilometrageIn_Cnt_u32: data-element=KilometrageIn.Cnt_u32
          REC_SecondeEcoulee_Cnt_u32: data-element=SecondeEcoulee.Cnt_u32
        data write access WRITE_CompteurTemporelVehiculeRaw_Cnt_u32: data-element=CompteurTemporelVehiculeRaw.Cnt_u32
        data write access WRITE_ISDAT4V2BSI552MsgRxTimeRaw_MSec_u32: data-element=ISDAT4V2BSI552MsgRxTimeRaw.MSec_u32
        data write access WRITE_Kilometrage_Cnt_u32: data-element=Kilometrage.Cnt_u32
        sync call SC_NxtrDiagMgr_GetNTCFailed: operation=NxtrDiagMgr.GetNTCFailed, timeout=0
        sync call SC_NxtrDiagMgr_SetNTCStatus: operation=NxtrDiagMgr.SetNTCStatus, timeout=0
      SrlComInput_MsgIsDatAbr_50D
        data receive point REC_ISDATABR50DMsgDLCError_Cnt_u08: data-element=ISDATABR50DMsgDLCError.Cnt_u08
        data receive point REC_ISDATABR50DMsgRxTime_MSec_u32: data-element=ISDATABR50DMsgRxTime.MSec_u32
        sync call SC_NxtrDiagMgr_SetNTCStatus: operation=NxtrDiagMgr.SetNTCStatus, timeout=0
      SrlComInput_MsgIsDatBsi_3F2
        6 x data receive point:
          REC_ColumnAngleSetpoint_Cnt_u16: data-element=ColumnAngleSetpoint.Cnt_u16
          REC_ISDATBSI3F2MsgDLCError_Cnt_u08: data-element=ISDATBSI3F2MsgDLCError.Cnt_u08
          REC_ISDATBSI3F2MsgRxTime_MSec_u32: data-element=ISDATBSI3F2MsgRxTime.MSec_u32
          REC_LKAState_Cnt_u08: data-element=LKAState.Cnt_u08
          REC_LKATrqFactReq_Cnt_u08: data-element=LKATrqFactReq.Cnt_u08
          REC_LXAActivation_Cnt_u08: data-element=LXAActivation.Cnt_u08
        data write access WRITE_LxaSeln_Cnt_lgc: data-element=LxaSeln.Cnt_lgc
        data write access WRITE_LxaTqFacReq_Uls_f32: data-element=LxaTqFacReq.Uls_f32
        sync call SC_NxtrDiagMgr_SetNTCStatus: operation=NxtrDiagMgr.SetNTCStatus, timeout=0
      SrlComInput_MsgIsDatBsi_412
        data receive point REC_ISDATBSI412MsgDLCError_Cnt_u08: data-element=ISDATBSI412MsgDLCError.Cnt_u08
        data receive point REC_ISDATBSI412MsgRxTime_MSec_u32: data-element=ISDATBSI412MsgRxTime.MSec_u32
        data receive point REC_ReqModeDA_Cnt_u08: data-element=ReqModeDA.Cnt_u08
        sync call SC_NxtrDiagMgr_SetNTCStatus: operation=NxtrDiagMgr.SetNTCStatus, timeout=0
      SrlComInput_MsgIsDatBsi_432
        6 x data receive point:
          REC_EtatPrincipSevIn_Cnt_u08: data-element=EtatPrincipSevIn.Cnt_u08
          REC_EtatReseauElecIn_Cnt_u08: data-element=EtatReseauElecIn.Cnt_u08
          REC_ISDATBSI432MsgDLCError_Cnt_u08: data-element=ISDATBSI432MsgDLCError.Cnt_u08
          REC_ISDATBSI432MsgRxTime_MSec_u32: data-element=ISDATBSI432MsgRxTime.MSec_u32
          REC_PowerSuppliesIn_Cnt_u08: data-element=PowerSuppliesIn.Cnt_u08
          REC_ShuntPositionIn_Cnt_u08: data-element=ShuntPositionIn.Cnt_u08
        4 x data write access:
          WRITE_EtatPrincipSev_Cnt_u08: data-element=EtatPrincipSev.Cnt_u08
          WRITE_EtatReseauElec_Cnt_u08: data-element=EtatReseauElec.Cnt_u08
          WRITE_PowerSupplies_Cnt_u08: data-element=PowerSupplies.Cnt_u08
          WRITE_ShuntPosition_Cnt_u08: data-element=ShuntPosition.Cnt_u08
        sync call SC_NxtrDiagMgr_SetNTCStatus: operation=NxtrDiagMgr.SetNTCStatus, timeout=0
      SrlComInput_MsgIsDatBsi_572
        data receive point REC_ConfigVhl_Cnt_u08: data-element=ConfigVhl.Cnt_u08
        data receive point REC_ISDATBSI572MsgDLCError_Cnt_u08: data-element=ISDATBSI572MsgDLCError.Cnt_u08
        data receive point REC_ISDATBSI572MsgRxTime_MSec_u32: data-element=ISDATBSI572MsgRxTime.MSec_u32
        sync call SC_NxtrDiagMgr_SetNTCStatus: operation=NxtrDiagMgr.SetNTCStatus, timeout=0
      SrlComInput_MsgIsDyn2Cmm_348
        data receive point REC_ISDYN2CMMMsgDLCError_Cnt_u08: data-element=ISDYN2CMMMsgDLCError.Cnt_u08
        data receive point REC_ISDYN2CMMMsgRxTime_MSec_u32: data-element=ISDYN2CMMMsgRxTime.MSec_u32
        sync call SC_NxtrDiagMgr_SetNTCStatus: operation=NxtrDiagMgr.SetNTCStatus, timeout=0
      SrlComInput_MsgIsDyn2Fre_3CD
        data receive point REC_AccelLat_Cnt_s16: data-element=AccelLat.Cnt_s16
        data receive point REC_ISDYN2FRE3CDMsgDLCError_Cnt_u08: data-element=ISDYN2FRE3CDMsgDLCError.Cnt_u08
        data receive point REC_ISDYN2FRE3CDMsgRxTime_MSec_u32: data-element=ISDYN2FRE3CDMsgRxTime.MSec_u32
        sync call SC_NxtrDiagMgr_SetNTCStatus: operation=NxtrDiagMgr.SetNTCStatus, timeout=0
      SrlComInput_MsgIsDynAas_2EB
        data receive point REC_ISDYNAASMsg_Cnt_u08: data-element=ISDYNAASMsg.Cnt_u08
        data receive point REC_ISDYNAASMsgDLCError_Cnt_u08: data-element=ISDYNAASMsgDLCError.Cnt_u08
        data receive point REC_ISDYNAASMsgRxTime_MSec_u32: data-element=ISDYNAASMsgRxTime.MSec_u32
        sync call SC_NxtrDiagMgr_SetNTCStatus: operation=NxtrDiagMgr.SetNTCStatus, timeout=0
      SrlComInput_MsgIsDynAbr_38D
        data receive point REC_ISDYNABRMsg_Cnt_u08: data-element=ISDYNABRMsg.Cnt_u08
        data receive point REC_ISDYNABRMsgDLCError_Cnt_u08: data-element=ISDYNABRMsgDLCError.Cnt_u08
        data receive point REC_ISDYNABRMsgRxTime_MSec_u32: data-element=ISDYNABRMsgRxTime.MSec_u32
        data send point SEND_VVHType_Cnt_u08: data-element=VVHType.Cnt_u08
        sync call SC_NxtrDiagMgr_SetNTCStatus: operation=NxtrDiagMgr.SetNTCStatus, timeout=0
        sync call SC_VHHTYPE_WriteBlock: operation=VHHTYPE.WriteBlock, timeout=0
      SrlComInput_MsgIsDynCds_34D
        data receive point REC_ISDYNCDS34DMsgDLCError_Cnt_u08: data-element=ISDYNCDS34DMsgDLCError.Cnt_u08
        data receive point REC_ISDYNCDS34DMsgRxTime_MSec_u32: data-element=ISDYNCDS34DMsgRxTime.MSec_u32
        sync call SC_NxtrDiagMgr_SetNTCStatus: operation=NxtrDiagMgr.SetNTCStatus, timeout=0
      SrlComInput_MsgIsDynCmm_208
        data receive point REC_ISDYNCMM208MsgDLCError_Cnt_u08: data-element=ISDYNCMM208MsgDLCError.Cnt_u08
        data receive point REC_ISDYNCMM208MsgRxTime_MSec_u32: data-element=ISDYNCMM208MsgRxTime.MSec_u32
        sync call SC_NxtrDiagMgr_SetNTCStatus: operation=NxtrDiagMgr.SetNTCStatus, timeout=0
      SrlComInput_MsgIsDynCmm_388
        data receive point REC_ISDYNCMM388MsgDLCError_Cnt_u08: data-element=ISDYNCMM388MsgDLCError.Cnt_u08
        data receive point REC_ISDYNCMM388MsgRxTime_MSec_u32: data-element=ISDYNCMM388MsgRxTime.MSec_u32
        data receive point REC_VitesseVehicleBV_Cnt_u16: data-element=VitesseVehicleBV.Cnt_u16
        data send point SEND_VVHType_Cnt_u08: data-element=VVHType.Cnt_u08
        sync call SC_NxtrDiagMgr_SetNTCStatus: operation=NxtrDiagMgr.SetNTCStatus, timeout=0
        sync call SC_VHHTYPE_WriteBlock: operation=VHHTYPE.WriteBlock, timeout=0
      SrlComInput_MsgIsDynVol_305
        data receive point REC_ISDYNVOLMsg_Cnt_u08: data-element=ISDYNVOLMsg.Cnt_u08
        data receive point REC_ISDYNVOLMsgDLCError_Cnt_u08: data-element=ISDYNVOLMsgDLCError.Cnt_u08
        data receive point REC_ISDYNVOLMsgRxTime_MSec_u32: data-element=ISDYNVOLMsgRxTime.MSec_u32
        sync call SC_NxtrDiagMgr_SetNTCStatus: operation=NxtrDiagMgr.SetNTCStatus, timeout=0
      SrlComInput_MsgIsInteElectronBsi_092
        data receive point REC_DiagIntegraElec_Cnt_u08: data-element=DiagIntegraElec.Cnt_u08
        data receive point REC_EffacDefaultDiag_Cnt_u08: data-element=EffacDefaultDiag.Cnt_u08
        data receive point REC_ModeDiag_Cnt_u08: data-element=ModeDiag.Cnt_u08
        sync call SC_SystemTime_DtrmnElapsedTime_mS_u16: operation=SystemTime.DtrmnElapsedTime_mS_u16, timeout=0
      SrlComInput_MsgProtoHs1DynUcf_5CD
        data receive point REC_PROTOHS1DYNUCF5CDMsg_Cnt_u08: data-element=PROTOHS1DYNUCF5CDMsg.Cnt_u08
        data receive point REC_PROTOHS1DYNUCF5CDMsgDLCError_Cnt_u08: data-element=PROTOHS1DYNUCF5CDMsgDLCError.Cnt_u08
        data receive point REC_PROTOHS1DYNUCF5CDMsgRxTime_MSec_u32: data-element=PROTOHS1DYNUCF5CDMsgRxTime.MSec_u32
        sync call SC_NxtrDiagMgr_SetNTCStatus: operation=NxtrDiagMgr.SetNTCStatus, timeout=0
        sync call SC_SystemTime_DtrmnElapsedTime_mS_u16: operation=SystemTime.DtrmnElapsedTime_mS_u16, timeout=0
        sync call SC_SystemTime_GetSystemTime_mS_u32: operation=SystemTime.GetSystemTime_mS_u32, timeout=0
      SrlComInput_Per1
        6 x data read access:
          READ_Batt_Volt_f32: data-element=Batt.Volt_f32
          READ_BusOff_Cnt_lgc: data-element=BusOff.Cnt_lgc
          READ_CTermActive_Cnt_lgc: data-element=CTermActive.Cnt_lgc
          READ_ESCOffsCfgSeld_Cnt_lgc: data-element=ESCOffsCfgSeld.Cnt_lgc
          READ_RxMsgsSrlComSvcDft_Cnt_lgc: data-element=RxMsgsSrlComSvcDft.Cnt_lgc
          READ_VehicleSpeed_Kph_f32: data-element=VehicleSpeed.Kph_f32
        25 x data receive point:
          REC_AnneeEcoule_Cnt_u08: data-element=AnneeEcoule.Cnt_u08
          REC_CompteurTemporelVehicule_Cnt_u32: data-element=CompteurTemporelVehicule.Cnt_u32
          REC_ComputerRazGCT_Cnt_u08: data-element=ComputerRazGCT.Cnt_u08
          REC_DiagMuxOn_Cnt_u08: data-element=DiagMuxOn.Cnt_u08
          REC_DmdDelestDA_Cnt_u08: data-element=DmdDelestDA.Cnt_u08
          REC_EtatMT_Cnt_u08: data-element=EtatMT.Cnt_u08
          REC_ISDAT4V2BSI552MsgRxTime_MSec_u32: data-element=ISDAT4V2BSI552MsgRxTime.MSec_u32
          REC_ISDATABR50DMsgRxTime_MSec_u32: data-element=ISDATABR50DMsgRxTime.MSec_u32
          REC_ISDATBSI3F2MsgRxTime_MSec_u32: data-element=ISDATBSI3F2MsgRxTime.MSec_u32
          REC_ISDATBSI412MsgRxTime_MSec_u32: data-element=ISDATBSI412MsgRxTime.MSec_u32
          REC_ISDATBSI432MsgRxTime_MSec_u32: data-element=ISDATBSI432MsgRxTime.MSec_u32
          REC_ISDATBSI572MsgRxTime_MSec_u32: data-element=ISDATBSI572MsgRxTime.MSec_u32
          REC_ISDATDIRAMsgTxInProgress_Cnt_lgc: data-element=ISDATDIRAMsgTxInProgress.Cnt_lgc
          REC_ISDATDIRAMsgTxTime_MSec_u32: data-element=ISDATDIRAMsgTxTime.MSec_u32
          REC_ISDYN2CMMMsgRxTime_MSec_u32: data-element=ISDYN2CMMMsgRxTime.MSec_u32
          REC_ISDYN2FRE3CDMsgRxTime_MSec_u32: data-element=ISDYN2FRE3CDMsgRxTime.MSec_u32
          REC_ISDYNAASMsgRxTime_MSec_u32: data-element=ISDYNAASMsgRxTime.MSec_u32
          REC_ISDYNABRMsgRxTime_MSec_u32: data-element=ISDYNABRMsgRxTime.MSec_u32
          REC_ISDYNCDS34DMsgRxTime_MSec_u32: data-element=ISDYNCDS34DMsgRxTime.MSec_u32
          REC_ISDYNCMM208MsgRxTime_MSec_u32: data-element=ISDYNCMM208MsgRxTime.MSec_u32
          REC_ISDYNCMM388MsgRxTime_MSec_u32: data-element=ISDYNCMM388MsgRxTime.MSec_u32
          REC_ISDYNVOLMsgRxTime_MSec_u32: data-element=ISDYNVOLMsgRxTime.MSec_u32
          REC_JourEcoule_Cnt_u16: data-element=JourEcoule.Cnt_u16
          REC_PROTOHS1DYNUCF5CDMsgRxTime_MSec_u32: data-element=PROTOHS1DYNUCF5CDMsgRxTime.MSec_u32
          REC_SecondeEcoulee_Cnt_u32: data-element=SecondeEcoulee.Cnt_u32
        data write access WRITE_ComputerRazGCTRaw_Cnt_u08: data-element=ComputerRazGCTRaw.Cnt_u08
        data write access WRITE_EtatMTRaw_Cnt_u08: data-element=EtatMTRaw.Cnt_u08
        5 x sync call, all with timeout=0:
          SC_EpsEn_OP_GET: operation=EpsEn.OP_GET
          SC_NxtrDiagMgr_GetNTCFailed: operation=NxtrDiagMgr.GetNTCFailed
          SC_NxtrDiagMgr_SetNTCStatus: operation=NxtrDiagMgr.SetNTCStatus
          SC_SystemTime_DtrmnElapsedTime_mS_u16: operation=SystemTime.DtrmnElapsedTime_mS_u16
          SC_SystemTime_GetSystemTime_mS_u32: operation=SystemTime.GetSystemTime_mS_u32
      SrlComInput_Per2: can-enter-exclusive-area=DmdDelestDa
        data read access READ_DefaultVehSpd_Cnt_lgc: data-element=DefaultVehSpd.Cnt_lgc
        4 x data receive point:
          REC_ESPDeconnecte_Cnt_u08: data-element=ESPDeconnecte.Cnt_u08
          REC_RegulAbr_Cnt_u08: data-element=RegulAbr.Cnt_u08
          REC_RegulEsp_Cnt_u08: data-element=RegulEsp.Cnt_u08
          REC_ReqLampeDefEsp_Cnt_u08: data-element=ReqLampeDefEsp.Cnt_u08
        data send point SEND_DmdDelestDaSts_Cnt_u08: data-element=DmdDelestDaSts.Cnt_u08
        data send point SEND_DmdDelestDaVld_Cnt_lgc: data-element=DmdDelestDaVld.Cnt_lgc
        35 x data write access:
          WRITE_AbsActv_Cnt_lgc: data-element=AbsActv.Cnt_lgc
          WRITE_AngleVolant_HwDeg_f32: data-element=AngleVolant.HwDeg_f32
          WRITE_APAAuthn_Cnt_lgc: data-element=APAAuthn.Cnt_lgc
          WRITE_ApaRelaxReq_Cnt_lgc: data-element=ApaRelaxReq.Cnt_lgc
          WRITE_APARequest_Cnt_lgc: data-element=APARequest.Cnt_lgc
          WRITE_ApaVehicleSpeedValid_Cnt_lgc: data-element=ApaVehicleSpeedValid.Cnt_lgc
          WRITE_BSIDataMissing_Cnt_lgc: data-element=BSIDataMissing.Cnt_lgc
          WRITE_CMMDataMissing_Cnt_lgc: data-element=CMMDataMissing.Cnt_lgc
          WRITE_ColAngleSetpoint_HwDeg_f32: data-element=ColAngleSetpoint.HwDeg_f32
          WRITE_CONSANGLECPK_Cnt_s16: data-element=CONSANGLECPK.Cnt_s16
          WRITE_CPKOK_Cnt_lgc: data-element=CPKOK.Cnt_lgc
          WRITE_DMDFCTCPK_Cnt_u08: data-element=DMDFCTCPK.Cnt_u08
          WRITE_ElectronicIntegration_Cnt_lgc: data-element=ElectronicIntegration.Cnt_lgc
          WRITE_EnergyModeState_Cnt_enum: data-element=EnergyModeState.Cnt_enum
          WRITE_EngOn_Cnt_lgc: data-element=EngOn.Cnt_lgc
          WRITE_EscAckFromSerlCom_Cnt_lgc: data-element=EscAckFromSerlCom.Cnt_lgc
          WRITE_EscActv_Cnt_lgc: data-element=EscActv.Cnt_lgc
          WRITE_EscDataVldFromSerlCom_Cnt_lgc: data-element=EscDataVldFromSerlCom.Cnt_lgc
          WRITE_EscEna_Cnt_lgc: data-element=EscEna.Cnt_lgc
          WRITE_EscFltPrsnt_Cnt_lgc: data-element=EscFltPrsnt.Cnt_lgc
          WRITE_EscOffsFromSerlCom_HwDeg_f32: data-element=EscOffsFromSerlCom.HwDeg_f32
          WRITE_EscPrecisionFromSerlCom_HwDeg_f32: data-element=EscPrecisionFromSerlCom.HwDeg_f32
          WRITE_IgnTimeOff_Cnt_u32: data-element=IgnTimeOff.Cnt_u32
          WRITE_LxaInpVld_Cnt_lgc: data-element=LxaInpVld.Cnt_lgc
          WRITE_LxaStateFilt_Cnt_enum: data-element=LxaStateFilt.Cnt_enum
          WRITE_MultiModeVld_Cnt_lgc: data-element=MultiModeVld.Cnt_lgc
          WRITE_PosSrvoHwAngle_HwDeg_f32: data-element=PosSrvoHwAngle.HwDeg_f32
          WRITE_ReqModeDAFinal_Cnt_enum: data-element=ReqModeDAFinal.Cnt_enum
          WRITE_SerialComAngleValid_Cnt_lgc: data-element=SerialComAngleValid.Cnt_lgc
          WRITE_SrlComVehSpd_Kph_f32: data-element=SrlComVehSpd.Kph_f32
          WRITE_ValidEngineStatus_Cnt_lgc: data-element=ValidEngineStatus.Cnt_lgc
          WRITE_VehicleLatAccel_MpSecSq_f32: data-element=VehicleLatAccel.MpSecSq_f32
          WRITE_VehicleLatAccelValid_Cnt_lgc: data-element=VehicleLatAccelValid.Cnt_lgc
          WRITE_VehicleSpeedValid_Cnt_lgc: data-element=VehicleSpeedValid.Cnt_lgc
          WRITE_VehTimeValid_Cnt_lgc: data-element=VehTimeValid.Cnt_lgc
        5 x sync call, all with timeout=0:
          SC_ElecInt_WriteBlock: operation=ElecInt.WriteBlock
          SC_NxtrDiagMgr_GetNTCFailed: operation=NxtrDiagMgr.GetNTCFailed
          SC_NxtrDiagMgr_GetNTCStatus: operation=NxtrDiagMgr.GetNTCStatus
          SC_SrlComDriver_SCom_ElecIntStart: operation=SrlComDriver_SCom.ElecIntStart
          SC_SrlComDriver_SCom_ElecIntStop: operation=SrlComDriver_SCom.ElecIntStop
      SrlComInput_SCom_GetNetworkDiagFltAcc
      SrlComInput_SCom_ManualVehSpd
      SrlComInput_SCom_ResetTimers
      SrlComInput_SCom_VehSpdControl
      SrlComInput_Trns1: can-enter-exclusive-area=EaShutdownTimeData
        5 x data receive point:
          REC_AnneeEcoule_Cnt_u08: data-element=AnneeEcoule.Cnt_u08
          REC_CompteurTemporelVehicule_Cnt_u32: data-element=CompteurTemporelVehicule.Cnt_u32
          REC_ISDAT4V2BSI552MsgRxTime_MSec_u32: data-element=ISDAT4V2BSI552MsgRxTime.MSec_u32
          REC_JourEcoule_Cnt_u16: data-element=JourEcoule.Cnt_u16
          REC_SecondeEcoulee_Cnt_u32: data-element=SecondeEcoulee.Cnt_u32
        sync call SC_NxtrDiagMgr_GetNTCFailed: operation=NxtrDiagMgr.GetNTCFailed, timeout=0
        sync call SC_ShutdownTime_WriteBlock: operation=ShutdownTime.WriteBlock, timeout=0
      SrlComInput_Trns2
        9 x data write access:
          WRITE_CompteurTemporelVehiculeRaw_Cnt_u32: data-element=CompteurTemporelVehiculeRaw.Cnt_u32
          WRITE_EtatPrincipSev_Cnt_u08: data-element=EtatPrincipSev.Cnt_u08
          WRITE_EtatReseauElec_Cnt_u08: data-element=EtatReseauElec.Cnt_u08
          WRITE_ISDAT4V2BSI552MsgRxTimeRaw_MSec_u32: data-element=ISDAT4V2BSI552MsgRxTimeRaw.MSec_u32
          WRITE_Kilometrage_Cnt_u32: data-element=Kilometrage.Cnt_u32
          WRITE_LxaSeln_Cnt_lgc: data-element=LxaSeln.Cnt_lgc
          WRITE_LxaTqFacReq_Uls_f32: data-element=LxaTqFacReq.Uls_f32
          WRITE_PowerSupplies_Cnt_u08: data-element=PowerSupplies.Cnt_u08
          WRITE_ShuntPosition_Cnt_u08: data-element=ShuntPosition.Cnt_u08
    service-needss:
      swc nv block needs VVHTYPE: n-data-sets=0, readonly=false, reliability=LOW, resistant-to-changed-sw=false, restore-at-start=false, write-only-once=false, writing-frequency=0, writing-priority=LOW, mirror-block=VVHTYPEData
      swc nv block needs ShutdownTime: n-data-sets=0, readonly=false, reliability=LOW, resistant-to-changed-sw=false, restore-at-start=false, write-only-once=false, writing-frequency=0, writing-priority=LOW, mirror-block=ShutdownTimeData
      swc nv block needs ElecInt: n-data-sets=0, readonly=false, reliability=LOW, resistant-to-changed-sw=false, restore-at-start=false, write-only-once=false, writing-frequency=0, writing-priority=LOW, mirror-block=ElecIntData
  swc implementation Ap_SrlComInput_Implementation: behavior=Ap_SrlComInput_InternalBehavior
    code-descriptors:
      code Code: type=SRC
